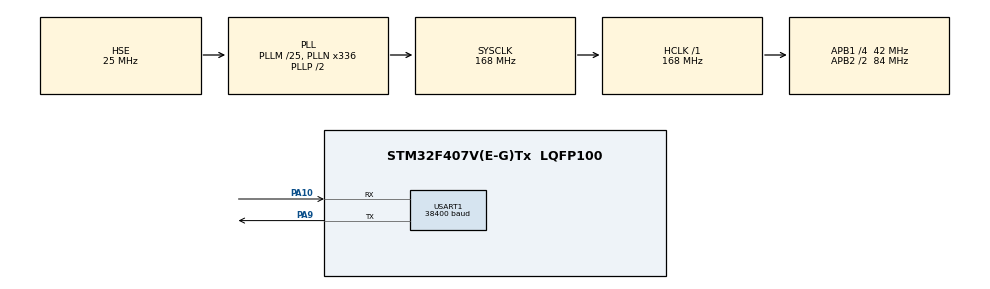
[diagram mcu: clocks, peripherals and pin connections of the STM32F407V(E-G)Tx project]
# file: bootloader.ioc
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Mcu.Family=STM32F4
Mcu.Name=STM32F407V(E-G)Tx
Mcu.Package=LQFP100
NVIC.PriorityGroup=NVIC_PRIORITYGROUP_4
PA10.Mode=Asynchronous
PA10.Signal=USART1_RX
PA9.Mode=Asynchronous
PA9.Signal=USART1_TX
PH0-OSC_IN.Mode=HSE-External-Oscillator
PH0-OSC_IN.Signal=RCC_OSC_IN
PH1-OSC_OUT.Mode=HSE-External-Oscillator
PH1-OSC_OUT.Signal=RCC_OSC_OUT
ProjectManager.HeapSize=0x200
ProjectManager.StackSize=0x400
ProjectManager.TargetToolchain=MDK-ARM V5.32
RCC.48MHZClocksFreq_Value=84000000
RCC.AHBFreq_Value=168000000
RCC.APB1CLKDivider=RCC_HCLK_DIV4
RCC.APB1Freq_Value=42000000
RCC.APB1TimFreq_Value=84000000
RCC.APB2CLKDivider=RCC_HCLK_DIV2
RCC.APB2Freq_Value=84000000
RCC.APB2TimFreq_Value=168000000
RCC.CortexFreq_Value=168000000
RCC.HCLKFreq_Value=168000000
RCC.HSE_VALUE=25000000
RCC.HSI_VALUE=16000000
RCC.LSE_VALUE=32768
RCC.PLLM=25
RCC.PLLN=336
RCC.PLLSourceVirtual=RCC_PLLSOURCE_HSE
RCC.SYSCLKFreq_VALUE=168000000
RCC.SYSCLKSource=RCC_SYSCLKSOURCE_PLLCLK
RCC.VCOOutputFreq_Value=336000000
USART1.BaudRate=38400
USART1.VirtualMode=VM_ASYNC
board=custom

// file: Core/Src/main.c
/* USER CODE BEGIN Header */
/**
 ******************************************************************************
 * @file           : main.c
 * @brief          : BootLoader — 115200 波特率
 ******************************************************************************
 */
/* USER CODE END Header */
#include "main.h"
#include "usart.h"
#include "gpio.h"

/* USER CODE BEGIN Includes */
#include "bootloader.h"
#include "bootloader_uart.h"
/* USER CODE END Includes */

void SystemClock_Config(void);

int main(void)
{

  /* MCU Configuration--------------------------------------------------------*/

  /* Reset of all peripherals, Initializes the Flash interface and the Systick. */
  HAL_Init();

  /* Configure the system clock */
  SystemClock_Config();

  /* Initialize all configured peripherals */
  MX_GPIO_Init();
  MX_USART1_UART_Init();
  /* USER CODE BEGIN 2 */

  #define S(s) HAL_UART_Transmit(&huart1, (uint8_t*)s, sizeof(s)-1, 5000)

  S("\r\n====================================\r\n");
  S("  STM32F407 IAP Bootloader v1.0\r\n");
  S("====================================\r\n");

  /* 检查升级标志: APP2 有新固件则复制到 APP1 */
  if (Bootloader_CheckUpdateFlag())
  {
      S("Update flag! Copying APP2->APP1...\r\n");
      if (bootloader_copy_app2_to_app1() == 0)
      {
          Bootloader_ClearUpdateFlag();   /* 拷贝成功才清除标志 */
          S("Update OK!\r\n");
      }
      else if (!bootloader_check_app2())
      {
          Bootloader_ClearUpdateFlag();   /* APP2 固件无效, 丢弃标志回退旧版本 */
          S("APP2 invalid, keep APP1\r\n");
      }
      else
      {
          S("Copy failed, retry on next boot\r\n");
      }
  }

  /* 检查 APP1 */
  if (!Bootloader_CheckAppValid())
  {
      S("APP1 invalid! IAP mode.\r\n");
      Bootloader_UART_Init(&huart1);
      while (1) { Bootloader_UART_Process(); }
  }

  /* 等待 3 秒 */
  S("Press 'U' for IAP, or wait...\r\n");
  {
      uint32_t t = HAL_GetTick();
      uint8_t ch;
      while ((HAL_GetTick() - t) < 3000)
      {
          if (HAL_UART_Receive(&huart1, &ch, 1, 10) == HAL_OK
              && (ch == 'U' || ch == 'u'))
          {
              /* 等第二个 'U'，防噪声误触发 */
              uint32_t t2 = HAL_GetTick();
              while ((HAL_GetTick() - t2) < 500) {
                  if (HAL_UART_Receive(&huart1, &ch, 1, 10) == HAL_OK
                      && (ch == 'U' || ch == 'u')) {
                      S("IAP triggered!\r\n");
                      Bootloader_UART_Init(&huart1);
                      S("Protocol running, send GET_INFO now\r\n");
                      while (1) { Bootloader_UART_Process(); }
                  }
              }
          }
      }
  }

  /* 跳转 APP1 */
  S("Jumping to APP1...\r\n");
  HAL_Delay(100);
  Bootloader_JumpToApp();

  S("Jump failed! IAP mode.\r\n");
  Bootloader_UART_Init(&huart1);
  while (1) { Bootloader_UART_Process(); }
  /* USER CODE END 2 */
}

void SystemClock_Config(void)
{
  RCC_OscInitTypeDef RCC_OscInitStruct = {0};
  RCC_ClkInitTypeDef RCC_ClkInitStruct = {0};

  /** Configure the main internal regulator output voltage
  */
  __HAL_RCC_PWR_CLK_ENABLE();
  __HAL_PWR_VOLTAGESCALING_CONFIG(PWR_REGULATOR_VOLTAGE_SCALE1);

  /** Initializes the RCC Oscillators according to the specified parameters
  * in the RCC_OscInitTypeDef structure.
  */
  RCC_OscInitStruct.OscillatorType = RCC_OSCILLATORTYPE_HSE;
  RCC_OscInitStruct.HSEState = RCC_HSE_ON;
  RCC_OscInitStruct.PLL.PLLState = RCC_PLL_ON;
  RCC_OscInitStruct.PLL.PLLSource = RCC_PLLSOURCE_HSE;
  RCC_OscInitStruct.PLL.PLLM = 25;
  RCC_OscInitStruct.PLL.PLLN = 336;
  RCC_OscInitStruct.PLL.PLLP = RCC_PLLP_DIV2;
  RCC_OscInitStruct.PLL.PLLQ = 4;
  if (HAL_RCC_OscConfig(&RCC_OscInitStruct) != HAL_OK)
  {
    Error_Handler();
  }

  /** Initializes the CPU, AHB and APB buses clocks
  */
  RCC_ClkInitStruct.ClockType = RCC_CLOCKTYPE_HCLK|RCC_CLOCKTYPE_SYSCLK
                              |RCC_CLOCKTYPE_PCLK1|RCC_CLOCKTYPE_PCLK2;
  RCC_ClkInitStruct.SYSCLKSource = RCC_SYSCLKSOURCE_PLLCLK;
  RCC_ClkInitStruct.AHBCLKDivider = RCC_SYSCLK_DIV1;
  RCC_ClkInitStruct.APB1CLKDivider = RCC_HCLK_DIV4;
  RCC_ClkInitStruct.APB2CLKDivider = RCC_HCLK_DIV2;

  if (HAL_RCC_ClockConfig(&RCC_ClkInitStruct, FLASH_LATENCY_5) != HAL_OK)
  {
    Error_Handler();
  }
}

void Error_Handler(void)
{
  __disable_irq();
  while (1)
  {
  }
}
